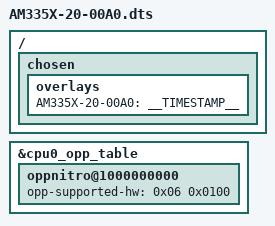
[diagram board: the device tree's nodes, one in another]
/*
 * Copyright (C) 2012 Texas Instruments Incorporated - http://www.ti.com/
 *
 * This program is free software; you can redistribute it and/or modify
 * it under the terms of the GNU General Public License version 2 as
 * published by the Free Software Foundation.
 */
/dts-v1/;
/plugin/;

/ {
	/*
	 * Helper to show loaded overlays under: /proc/device-tree/chosen/overlays/
	 */
	fragment@0 {
		target-path="/";
		__overlay__ {

			chosen {
				overlays {
					AM335X-20-00A0 = __TIMESTAMP__;
				};
			};
		};
	};

	fragment@1 {
		target = <&cpu0_opp_table>;
		__overlay__ {
			/*
			 * All PG 2.0 silicon may not support 1GHz but some of the early
			 * BeagleBone Blacks have PG 2.0 silicon which is guaranteed
			 * to support 1GHz OPP so enable it for PG 2.0 on this board.
			 */
			oppnitro@1000000000 {
				opp-supported-hw = <0x06 0x0100>;
			};
		};
	};
};
